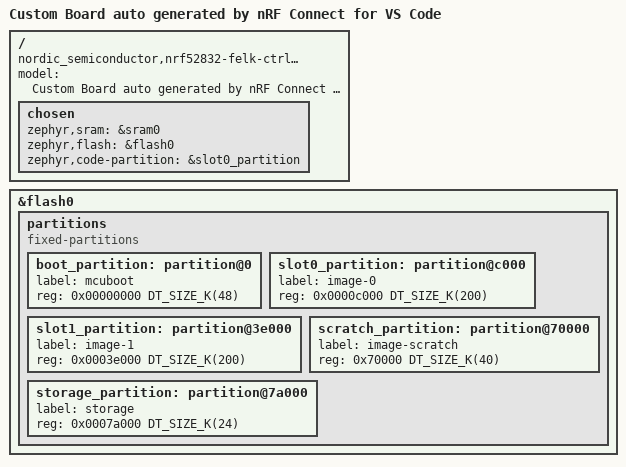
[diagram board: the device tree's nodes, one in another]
/dts-v1/;
#include <nordic/nrf52832_qfaa.dtsi>
#include "nrf52832_felk_ctrl_board-pinctrl.dtsi"

/ {
	model = "Custom Board auto generated by nRF Connect for VS Code";
	compatible = "nordic_semiconductor,nrf52832-felk-ctrl-board";

	chosen {
		zephyr,sram = &sram0;
		zephyr,flash = &flash0;
		zephyr,code-partition = &slot0_partition;
	};
};

&flash0 {
	partitions {
		compatible = "fixed-partitions";
		#address-cells = <1>;
		#size-cells = <1>;

		boot_partition: partition@0 {
			label = "mcuboot";
			reg = <0x00000000 DT_SIZE_K(48)>;
		};

		slot0_partition: partition@c000 {
			label = "image-0";
			reg = <0x0000c000 DT_SIZE_K(200)>;
		};

		slot1_partition: partition@3e000 {
			label = "image-1";
			reg = <0x0003e000 DT_SIZE_K(200)>;
		};

		scratch_partition: partition@70000 {
			label = "image-scratch";
			reg = <0x70000 DT_SIZE_K(40)>;
		};

		storage_partition: partition@7a000 {
			label = "storage";
			reg = <0x0007a000 DT_SIZE_K(24)>;
		};
	};
};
